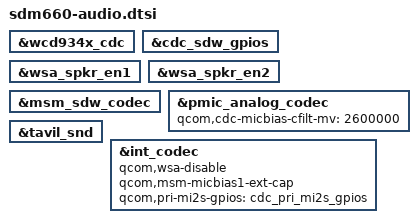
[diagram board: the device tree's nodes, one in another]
&wcd934x_cdc {
	/delete-node/ msm_cdc_pinctrl_usbc_audio_en1;
	/delete-node/ msm_cdc_pinctrl_usbc_audio_en2;
};

&cdc_sdw_gpios {
	/delete-property/ pinctrl-names;
	/delete-property/ pinctrl-0;
	/delete-property/ pinctrl-1;
};

&wsa_spkr_en1 {
	/delete-property/ pinctrl-names;
	/delete-property/ pinctrl-0;
	/delete-property/ pinctrl-1;
};

&wsa_spkr_en2 {
	/delete-property/ pinctrl-names;
	/delete-property/ pinctrl-0;
	/delete-property/ pinctrl-1;
};

&msm_sdw_codec {
	/delete-property/ qcom,cdc-sdw-gpios;
};

&pmic_analog_codec {
	qcom,cdc-micbias-cfilt-mv = <2600000>;
};

&tavil_snd {
	/delete-property/ qcom,usbc-analog-en1_gpio;
	/delete-property/ qcom,usbc-analog-en2_n_gpio;
};

&int_codec {
	qcom,wsa-disable;
	qcom,msm-micbias1-ext-cap;
	/delete-property/ qcom,msm-micbias2-ext-cap;
	/delete-property/ qcom,us-euro-gpios;
	qcom,pri-mi2s-gpios = <&cdc_pri_mi2s_gpios>;
};
